# STM32N645xx register map
File version: 1.0
Registers are 32-bit, read-write, reset 0x0 unless marked. A register's access mark holds for its fields unless they carry their own. Offsets are from the block's base; [hi:lo] are bit positions; {n}, {i} and the like mark numbered series; 'fields as' and 'values as' point back to an identical list.

## RISAF1 — RISAF Resource Isolation Slave Unit for Address Space Protection (full version) (RIF User Spec Rev 1.0.14)
Base 0x44026000
Same registers: RISAF2 0x44027000, RISAF3 0x44028000, RISAF6 0x4402B000, RISAF7 0x4402C000, RISAF8 0x4402D000, RISAF9 0x4402E000, RISAF11 0x44030000, RISAF12 0x44031000, RISAF13 0x44032000, RISAF14 0x44033000, RISAF21 0x44035000, RISAF22 0x44036000, RISAF23 0x44037000
0x00 CR — RISAF Configuration register
  [0] GLOCK — Global lock
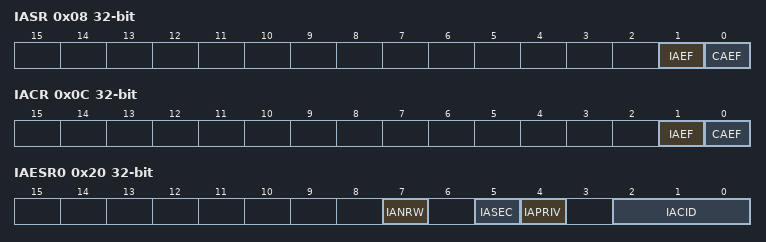
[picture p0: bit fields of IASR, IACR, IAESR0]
0x08 IASR — RISAF Illegal access status register
  [1] IAEF — Illegal access error flag
  [0] CAEF — Configuration access error flag
0x0C IACR — RISAF Illegal access clear register
  fields as IASR
0x20 IAESR0 — RISAF Illegal access error status register
  [7] IANRW — Illegal access read/write
  [5] IASEC — Illegal access security
  [4] IAPRIV — Illegal access privileged
  [2:0] IACID — Illegal access compartment ID
0x24 IADDR0 — RISAF Illegal address register
  [31:0] IADD — Illegal address
{0x40+0x40*i} CFGR{i} (i=0..14) — RISAF Region X configuration register
{0x44+0x40*i} STARTR{i} (i=0..14) — RISAF Region X start address register
{0x48+0x40*i} ENDR{i} (i=0..14) — RISAF Region X end address register
{0x4C+0x40*i} CIDCFGR{i} (i=0..14) — RISAF Region X CID configuration register
{0x50+0x40*i} ACFGR{i} (i=0..14) — RISAF Region X subregion A configuration register
{0x54+0x40*i} ASTARTR{i} (i=0..14) — RISAF Region X subregion A start address register
{0x58+0x40*i} AENDR{i} (i=0..14) — RISAF Region X subregion A end address register
{0x5C+0x40*i} ANESTR{i} (i=0..14) — RISAF Region X subregion A nested mode register
{0x60+0x40*i} BCFGR{i} (i=0..14) — RISAF Region X subregion B configuration register
{0x64+0x40*i} BSTARTR{i} (i=0..14) — RISAF Region X subregion B start address register
{0x68+0x40*i} BENDR{i} (i=0..14) — RISAF Region X subregion B end address register
{0x6C+0x40*i} BNESTR{i} (i=0..14) — RISAF Region X subregion B nested mode register

## VREFBUF
Base 0x46003C00
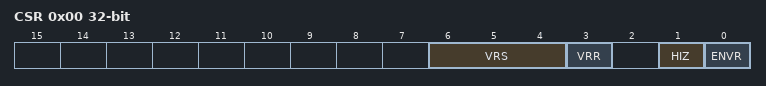
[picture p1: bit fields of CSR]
0x00 CSR — VREFBUF control and status register
  [6:4] VRS — Voltage reference scale
  [3] VRR — Voltage reference buffer ready
  [1] HIZ — High impedance mode
  [0] ENVR — Voltage reference buffer enable
0x04 CCR — VREFBUF calibration and control register
  [5:0] TRIM — TRIM[5:0] bits (Trimming code)

## TAMP — Tamper and backup registers
Base 0x46004400
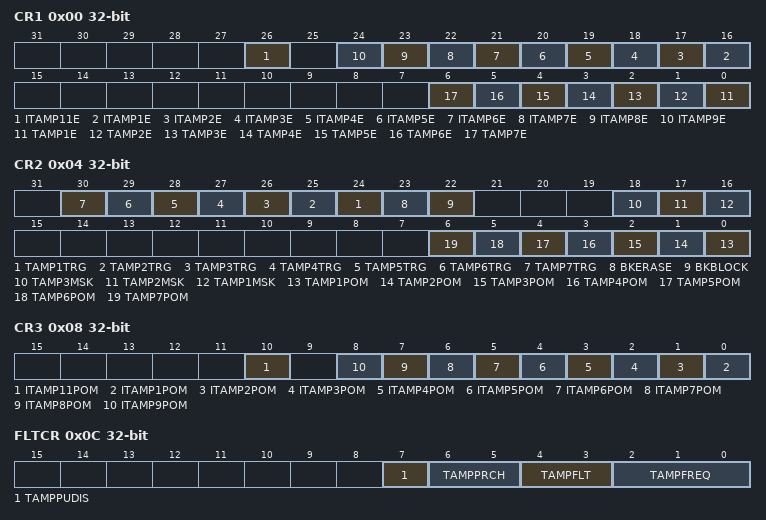
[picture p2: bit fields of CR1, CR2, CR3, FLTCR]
0x00 CR1 — TAMP configuration register 1
  [26] ITAMP11E, [n+15] ITAMP{n}E (n=1..9), [n-1] TAMP{n}E (n=1..7)
0x04 CR2 — TAMP configuration register 2
  [n+23] TAMP{n}TRG (n=1..7), [23] BKERASE, [22] BKBLOCK, [18] TAMP3MSK, [17] TAMP2MSK, [16] TAMP1MSK, [n-1] TAMP{n}POM (n=1..7)
0x08 CR3 — TAMP configuration register 3
  [10] ITAMP11POM, [n-1] ITAMP{n}POM (n=1..9)
0x0C FLTCR — TAMP filter control register
  [7] TAMPPUDIS
  [6:5] TAMPPRCH
    0=DURATION_1RTCCLK (Tamper pins are pre-charged before sampling during 1 RTCCLK cycle); 1=DURATION_2RTCCLK (Tamper pins are pre-charged before sampling during 2 RTCCLK cycles); 2=DURATION_4RTCCLK (Tamper pins are pre-charged before sampling during 4 RTCCLK cycles); 3=DURATION_8RTCCLK (Tamper pins are pre-charged before sampling during 8 RTCCLK cycles)
  [4:3] TAMPFLT
    0=DISABLE (Tamper filter is disabled); 1=FILTER_2SAMPLE (Tamper is activated after 2 consecutive samples at the active level); 2=FILTER_4SAMPLE (Tamper is activated after 4 consecutive samples at the active level); 3=FILTER_8SAMPLE (Tamper is activated after 8 consecutive samples at the active level)
  [2:0] TAMPFREQ
    0=SAMPLFREQDIV_32768 (Each of the tamper inputs are sampled with a frequency = RTCCLK / 32768); 1=SAMPLFREQDIV_16384 (Each of the tamper inputs are sampled with a frequency = RTCCLK / 16384); 2=SAMPLFREQDIV_8192 (Each of the tamper inputs are sampled with a frequency = RTCCLK / 8192); 3=SAMPLFREQDIV_4096 (Each of the tamper inputs are sampled with a frequency = RTCCLK / 4096); 4=SAMPLFREQDIV_2048 (Each of the tamper inputs are sampled with a frequency = RTCCLK / 2048); 5=SAMPLFREQDIV_1024 (Each of the tamper inputs are sampled with a frequency = RTCCLK / 1024); 6=SAMPLFREQDIV_512 (Each of the tamper inputs are sampled with a frequency = RTCCLK / 512); 7=SAMPLFREQDIV_256 (Each of the tamper inputs are sampled with a frequency = RTCCLK / 256)
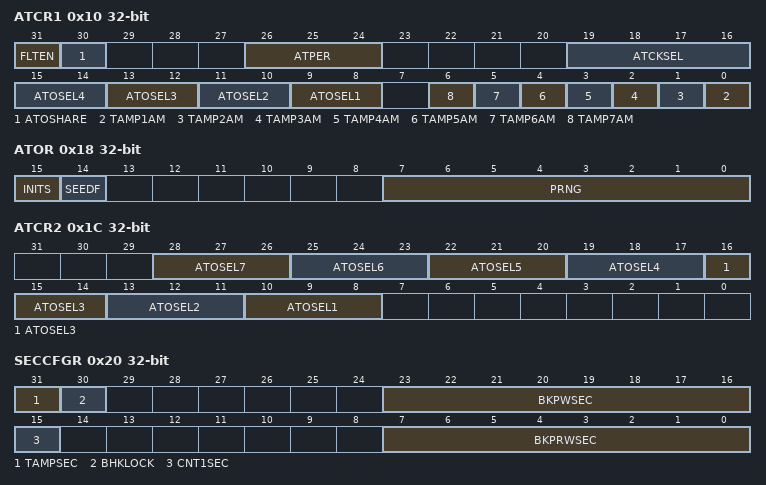
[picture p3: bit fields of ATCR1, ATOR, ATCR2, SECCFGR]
0x10 ATCR1 — TAMP filter control register 1
  [31] FLTEN, [30] ATOSHARE, [26:24] ATPER, [19:16] ATCKSEL, [2n+7:2n+6] ATOSEL{n} (n=1..4), [n-1] TAMP{n}AM (n=1..7)
0x14 ATSEEDR — TAMP active tamper seed register
  [31:0] SEED
0x18 ATOR — TAMP active tamper output register
  [15] INITS, [14] SEEDF, [7:0] PRNG
0x1C ATCR2 — TAMP filter control register 2
  [3n+7:3n+5] ATOSEL{n} (n=1..7)
0x20 SECCFGR — TAMP secure mode control register
  [31] TAMPSEC
    1=YES (TAMP full secure); 0=NO (TAMP is not secure)
  [30] BHKLOCK
  [23:16] BKPWSEC
  [15] CNT1SEC
  [7:0] BKPRWSEC
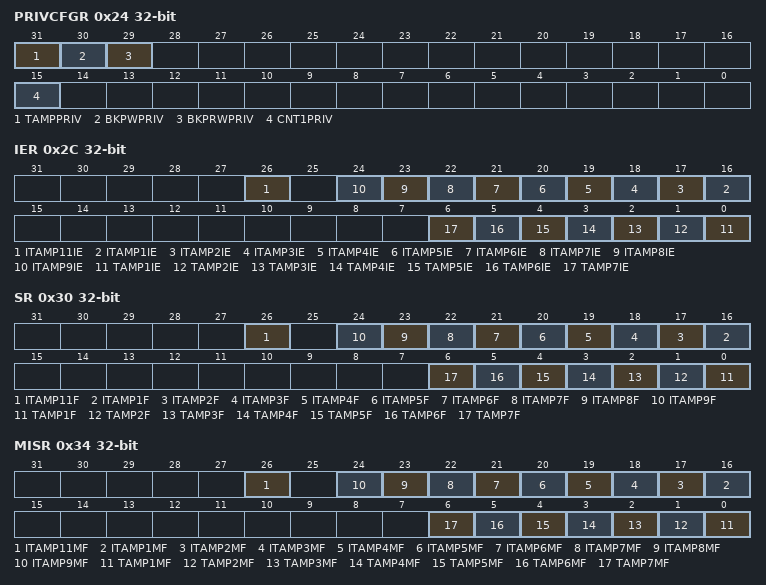
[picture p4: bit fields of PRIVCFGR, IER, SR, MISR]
0x24 PRIVCFGR — TAMP privilege mode control register
  [31] TAMPPRIV
    1=YES (TAMP full privilege); 0=NO (TAMP is not privilege)
  [30] BKPWPRIV
  [29] BKPRWPRIV
  [15] CNT1PRIV
0x2C IER — TAMP interrupt enable register
  [26] ITAMP11IE, [n+15] ITAMP{n}IE (n=1..9), [n-1] TAMP{n}IE (n=1..7)
0x30 SR — TAMP status register
  [26] ITAMP11F, [n+15] ITAMP{n}F (n=1..9), [n-1] TAMP{n}F (n=1..7)
0x34 MISR — TAMP masked interrupt status register
  [26] ITAMP11MF, [n+15] ITAMP{n}MF (n=1..9), [n-1] TAMP{n}MF (n=1..7)
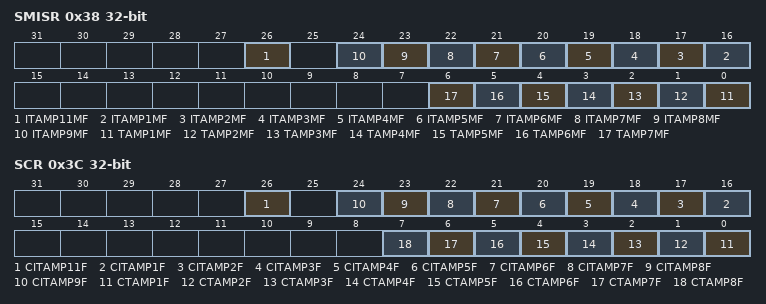
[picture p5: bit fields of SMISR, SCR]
0x38 SMISR — TAMP secure masked interrupt status register
  [26] ITAMP11MF, [n+15] ITAMP{n}MF (n=1..9), [n-1] TAMP{n}MF (n=1..7)
0x3C SCR — TAMP status clear register
  [26] CITAMP11F, [n+15] CITAMP{n}F (n=1..9), [n-1] CTAMP{n}F (n=1..8)
0x40 COUNT1R — TAMP monotonic counter register
  [31:0] COUNT
0x50 OR — TAMP option register
  [0] VCOREMEN
0x54 RPCFGR — TAMP resources protection configuration register
  [0] RPCFG0
{0x100+4i} BKP{i}R (i=0..31) — TAMP backup register {i}
